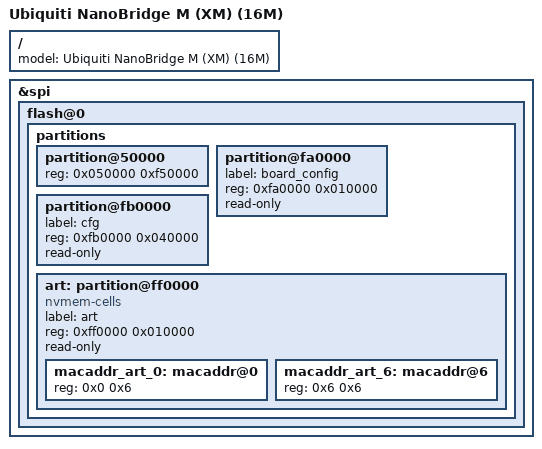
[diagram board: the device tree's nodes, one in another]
// SPDX-License-Identifier: GPL-2.0-or-later OR MIT

#include "ar7241_ubnt_nanobridge-m.dts"

/ {
	model = "Ubiquiti NanoBridge M (XM) (16M)";
};

&spi {
	flash@0 {
		partitions {
			partition@50000 {
				reg = <0x050000 0xf50000>;
			};

			/delete-node/ partition@7a0000;
			partition@fa0000 {
				label = "board_config";
				reg = <0xfa0000 0x010000>;
				read-only;
			};

			/delete-node/ partition@7b0000;
			partition@fb0000 {
				label = "cfg";
				reg = <0xfb0000 0x040000>;
				read-only;
			};

			/delete-node/ partition@7f0000;
			art: partition@ff0000 {
				label = "art";
				reg = <0xff0000 0x010000>;
				read-only;

				compatible = "nvmem-cells";
				#address-cells = <1>;
				#size-cells = <1>;

				macaddr_art_0: macaddr@0 {
					reg = <0x0 0x6>;
				};

				macaddr_art_6: macaddr@6 {
					reg = <0x6 0x6>;
				};
			};
		};
	};
};
